VERSION ""

NS_ :

BS_:

BU_: XXX

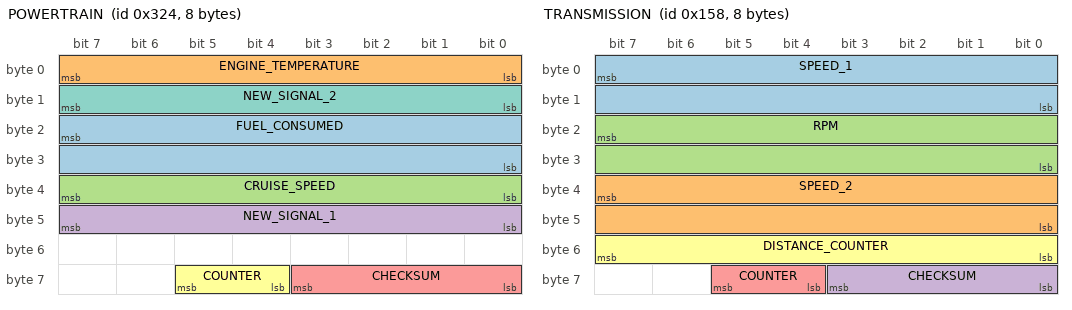
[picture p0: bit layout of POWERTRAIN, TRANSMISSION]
BO_ 804 POWERTRAIN: 8 XXX
 SG_ FUEL_CONSUMED : 23|16@0+ (1,0) [0|65535] "" XXX
 SG_ ENGINE_TEMPERATURE : 7|8@0+ (1,0) [0|255] "Degrees Celsius" XXX
 SG_ CRUISE_SPEED : 39|8@0+ (1,0) [0|255] "km/h" XXX
 SG_ NEW_SIGNAL_1 : 47|8@0- (1,0) [0|255] "" XXX
 SG_ CHECKSUM : 56|4@1+ (1,0) [0|15] "" XXX
 SG_ COUNTER : 61|2@0+ (1,0) [0|3] "" XXX
 SG_ NEW_SIGNAL_2 : 8|8@1+ (1,0) [0|255] "" XXX

BO_ 660 LIGHTS: 8 XXX
 SG_ LEFT_TURN_SIGNAL : 5|1@0+ (1,0) [0|1] "" XXX
 SG_ RIGHT_TURN_SIGNAL : 6|1@0+ (1,0) [0|1] "" XXX

BO_ 344 TRANSMISSION: 8 XXX
 SG_ SPEED_1 : 7|16@0+ (0.01,0) [0|65535] "km/h" XXX
 SG_ SPEED_2 : 39|16@0+ (0.01,0) [0|65535] "km/h" XXX
 SG_ RPM : 23|16@0+ (1,0) [0|65535] "" XXX
 SG_ CHECKSUM : 56|4@1+ (1,0) [0|15] "" XXX
 SG_ COUNTER : 61|2@0+ (1,0) [0|3] "" XXX
 SG_ DISTANCE_COUNTER : 55|8@0+ (1,0) [0|255] "" XXX
